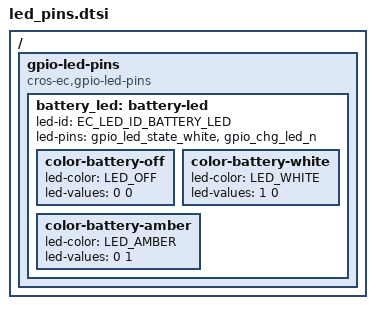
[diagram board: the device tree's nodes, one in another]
/* Copyright 2024 The ChromiumOS Authors
 * Use of this source code is governed by a BSD-style license that can be
 * found in the LICENSE file.
 */

 / {
    gpio-led-pins {
		compatible = "cros-ec,gpio-led-pins";

		battery_led: battery-led {
			led-id = "EC_LED_ID_BATTERY_LED";
			led-pins = <&gpio_led_state_white
                    &gpio_chg_led_n>;

			color-battery-off {
				led-color = "LED_OFF";
				led-values = <0 0>;
			};

			color-battery-white {
				led-color = "LED_WHITE";
				led-values = <1 0>;
			};

            color-battery-amber {
				led-color = "LED_AMBER";
				led-values = <0 1>;
			};
		};
	};
 };
